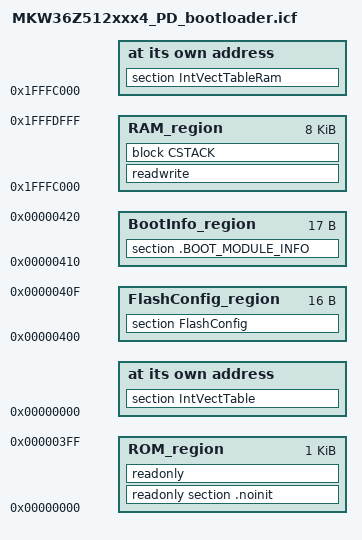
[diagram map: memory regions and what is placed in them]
/******************* Map of Kinetis FLASH ***********************************

  +---------------+
  |               |
  |               |
  |  Application  |
  |               |
  |               |
  +---------------+ - __region_BOOT_ROM_end__
  | Bootloader    |
  +---------------+ - __region_BOOT_ROM_start__

*****************************************************************************/

/*- Defining Symbols -*/
define exported symbol __ROM_SIZE__                = 0x00080000; /* 512KB */
define exported symbol __region_BOOT_ROM_start__   = 0x00000000;

define exported symbol __region_BOOT_ROM_end__     = 0x00001FFF; /* 8K */
define symbol __region_RAM_start__   = 0x1FFFC000;
define symbol __region_RAM_end__     = 0x1FFFDFFF;

/*-Sizes-*/
define symbol __size_cstack__ = 0x1000;
define symbol __IntVectTable_start__ = __region_BOOT_ROM_start__;
define symbol __IntVectTable_end__   = __region_BOOT_ROM_start__ + 0x3F;
define exported symbol __BOOT_STACK_ADDRESS = __region_RAM_end__ - 7;

if (isdefinedsymbol(__heap_size__)) {
  define symbol __size_heap__          = __heap_size__;
} else {
  define symbol __size_heap__          = 0;
}

define symbol __FlashConfig_start__   = 0x00000400;
define symbol __FlashConfig_end__     = 0x0000040f;

define symbol __Boot_Info_start__ = __FlashConfig_end__ + 1;
define symbol __Boot_Info_len__ = 0x10;
define symbol __Boot_Info_end__ = __Boot_Info_start__ + __Boot_Info_len__;

define block CSTACK    with alignment = 8, size = __size_cstack__   { };

/*** Memory Regions ***/
define memory mem with size = 4G;
define region ROM_region   = mem:[from __region_BOOT_ROM_start__ to (__FlashConfig_start__ - 1)] | [from (__Boot_Info_end__ + 1)  to __region_BOOT_ROM_end__];
define region RAM_region   = mem:[from __region_RAM_start__   to __region_RAM_end__];
define region FlashConfig_region  = mem:[from __FlashConfig_start__ to __FlashConfig_end__];
define region BootInfo_region = mem:[from __Boot_Info_start__ to __Boot_Info_end__];

/*** Initialization ***/
do not initialize   { readwrite };
do not initialize   { section .noinit };
initialize manually { section .data};
initialize by copy  { section .textrw };

/*** Memory placements ***/
place at address mem: __IntVectTable_start__ { section IntVectTable };
place at address mem: __region_RAM_start__ { section IntVectTableRam };
place in ROM_region          { readonly section .noinit };
place in ROM_region          { readonly };
place in RAM_region          { readwrite };
place in RAM_region          { block CSTACK };
place in FlashConfig_region  { section FlashConfig };
place in BootInfo_region     { section .BOOT_MODULE_INFO};
